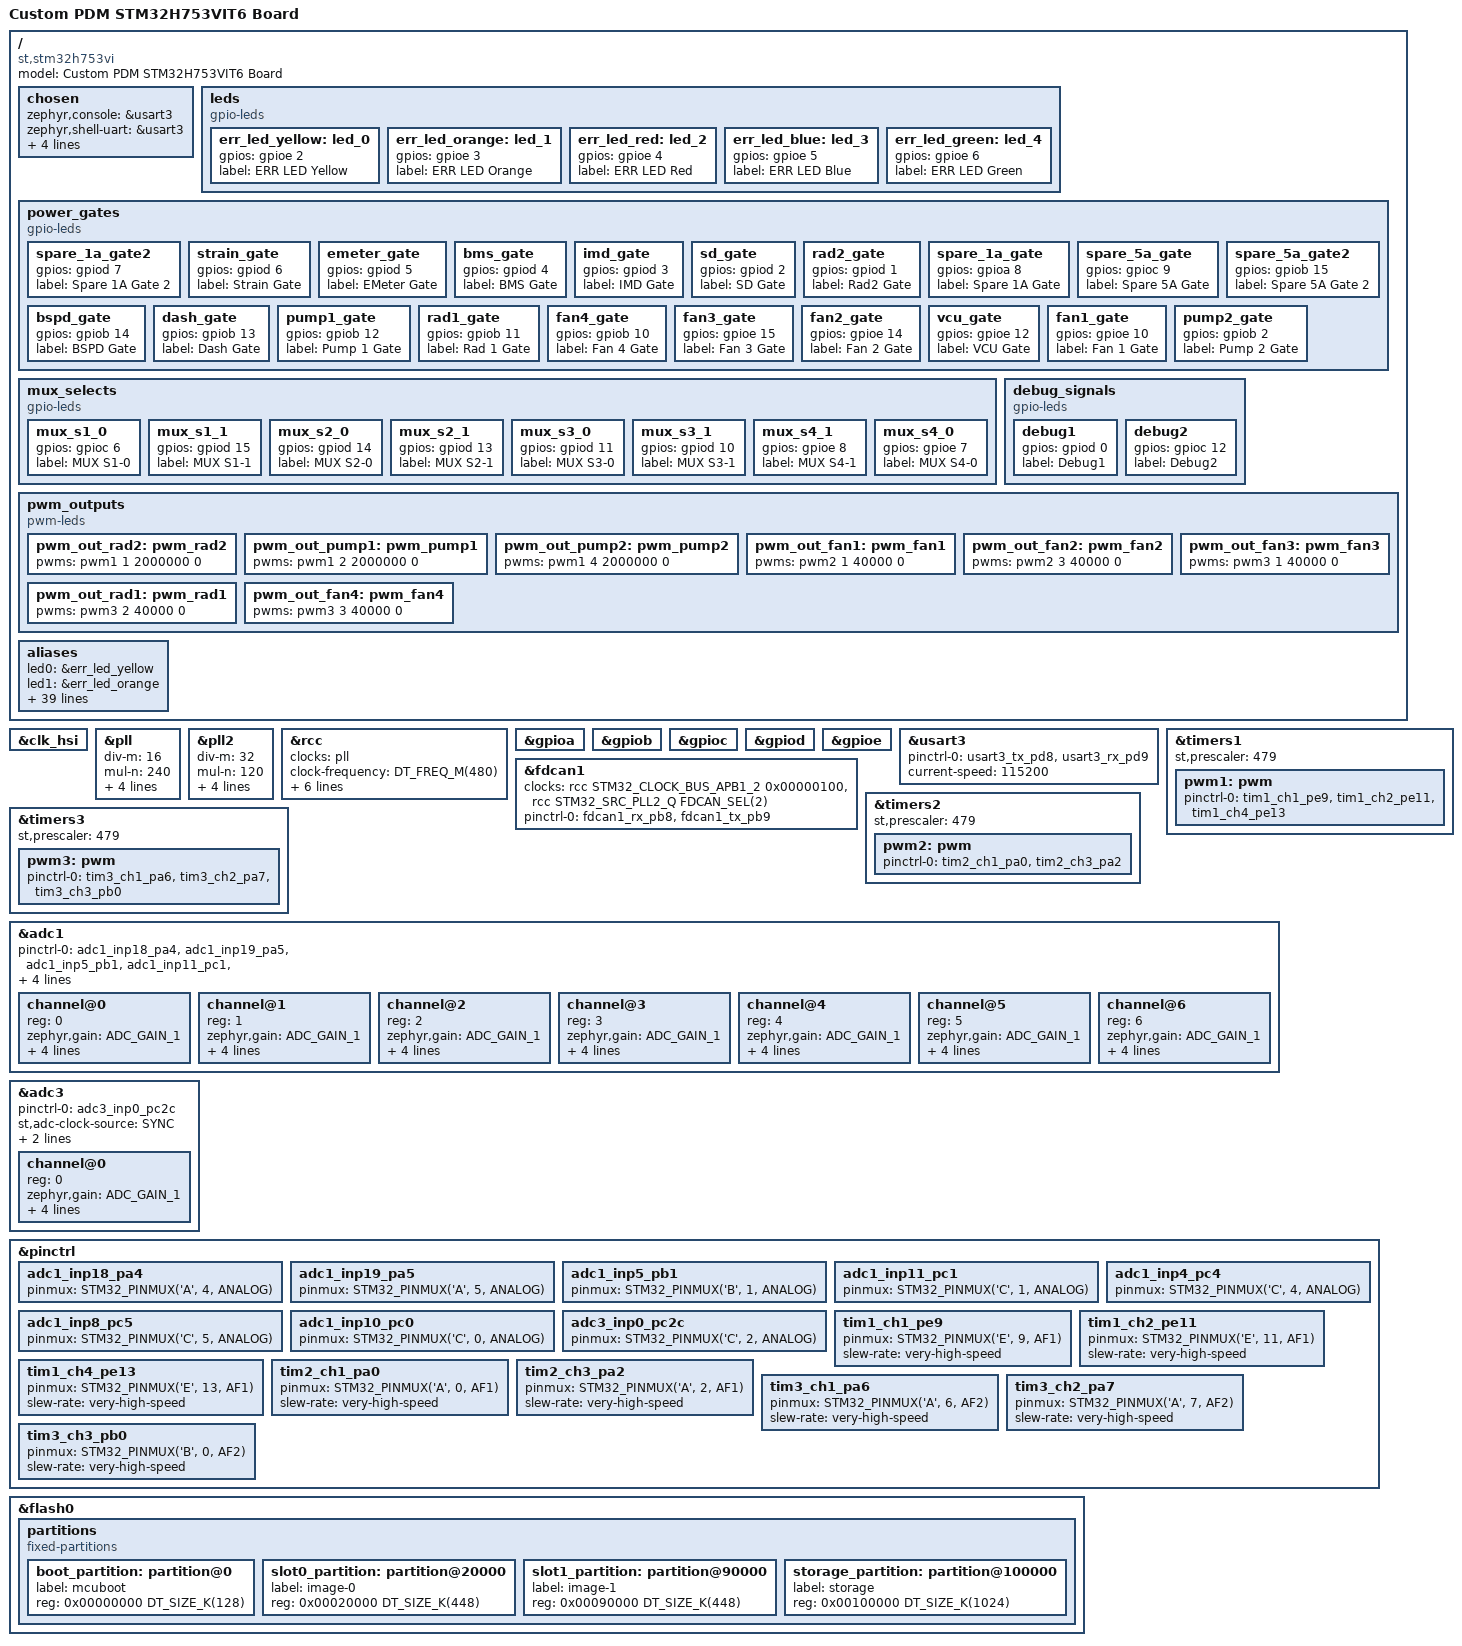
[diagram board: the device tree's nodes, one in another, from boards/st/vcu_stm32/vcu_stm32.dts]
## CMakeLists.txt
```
# SPDX-License-Identifier: Apache-2.0
cmake_minimum_required(VERSION 3.20.0)

#generates compile_commands.json for clangd to LSP correctly. 
set(CMAKE_EXPORT_COMPILE_COMMANDS ON)

set_source_files_properties(src/*.cpp PROPERTIES LANGUAGE CXX)

get_filename_component(_app_root "${CMAKE_CURRENT_SOURCE_DIR}" ABSOLUTE)
set(BOARD_ROOT "${_app_root}")


find_package(Zephyr REQUIRED HINTS $ENV{ZEPHYR_BASE})
project(pdm)

# Add include/ directory to include paths
target_include_directories(app PRIVATE
    ${CMAKE_CURRENT_SOURCE_DIR}/include
)

# Gather all C and C++ source files under src/
file(GLOB_RECURSE APP_SOURCES
    ${CMAKE_CURRENT_SOURCE_DIR}/src/*.c
    ${CMAKE_CURRENT_SOURCE_DIR}/src/*.cpp
)

# Add sources to app target
target_sources(app PRIVATE ${APP_SOURCES})
```

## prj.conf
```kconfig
CONFIG_CAN=y
CONFIG_GPIO=y
CONFIG_ADC=y
CONFIG_LOG=y
CONFIG_PWM=y
CONFIG_LOG_BACKEND_RTT=y
CONFIG_LOG_BACKEND_UART=n
CONFIG_USE_SEGGER_RTT=y
CONFIG_SEGGER_RTT_BUFFER_SIZE_UP=4096
CONFIG_UART_CONSOLE=n
CONFIG_RTT_CONSOLE=y
CONFIG_LOG_MODE_IMMEDIATE=y
CONFIG_LOG_DEFAULT_LEVEL=4
CONFIG_LOG_OVERRIDE_LEVEL=4
CONFIG_TRAP_UNALIGNED_ACCESS=n
CONFIG_LOG_BACKEND_FORMAT_TIMESTAMP=y
CONFIG_LOG_BACKEND_SHOW_COLOR=y
CONFIG_MAIN_STACK_SIZE=8192

CONFIG_FAULT_DUMP=2


CONFIG_CBPRINTF_FP_SUPPORT=y

CONFIG_CPP=y
CONFIG_CPP_EXCEPTIONS=y
CONFIG_GLIBCXX_LIBCPP=y
CONFIG_CAN_STATS=y

# Keep your custom compiler flag:
CONFIG_COMPILER_OPT="-ftrack-macro-expansion=0"
CONFIG_THREAD_MONITOR=y
CONFIG_THREAD_STACK_INFO=y
CONFIG_HEAP_MEM_POOL_SIZE=16384
CONFIG_SYSTEM_WORKQUEUE_STACK_SIZE=2048
CONFIG_SYS_HEAP_RUNTIME_STATS=y
CONFIG_PRINTK=y

CONFIG_ARM_MPU=n

CONFIG_THREAD_RUNTIME_STATS=y
CONFIG_DEBUG_OPTIMIZATIONS=y

CONFIG_SCHED_THREAD_USAGE=y
CONFIG_CPU_LOAD=y
CONFIG_STATS=y
```

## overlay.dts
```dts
    user_button: user_button {
        gpios = <&gpioc 13 GPIO_ACTIVE_LOW>;
        label = "USER_BUTTON";
    };
```

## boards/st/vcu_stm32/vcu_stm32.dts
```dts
/*
 * Copyright (c) 2025 PDM Team
 * SPDX-License-Identifier: Apache-2.0
 */

/dts-v1/;
#include <st/h7/stm32h753Xi.dtsi>
#include <st/h7/stm32h753vitx-pinctrl.dtsi>
#include <zephyr/dt-bindings/input/input-event-codes.h>
#include <zephyr/dt-bindings/gpio/gpio.h>

/ {
	model = "Custom PDM STM32H753VIT6 Board";
	compatible = "st,stm32h753vi";

	chosen {
		zephyr,console    = &usart3;
		zephyr,shell-uart = &usart3;
		zephyr,sram       = &sram0;
		zephyr,flash      = &flash0;
		zephyr,dtcm       = &dtcm;
		zephyr,canbus     = &fdcan1;
	};

	/* ------------------------------------------------------------------ */
	/* Status LEDs                                                          */
	/* ------------------------------------------------------------------ */
	leds {
		compatible = "gpio-leds";
		err_led_yellow: led_0 {
			gpios = <&gpioe 2 GPIO_ACTIVE_HIGH>;
			label = "ERR LED Yellow";
		};
		err_led_orange: led_1 {
			gpios = <&gpioe 3 GPIO_ACTIVE_HIGH>;
			label = "ERR LED Orange";
		};
		err_led_red: led_2 {
			gpios = <&gpioe 4 GPIO_ACTIVE_HIGH>;
			label = "ERR LED Red";
		};
		err_led_blue: led_3 {
			gpios = <&gpioe 5 GPIO_ACTIVE_HIGH>;
			label = "ERR LED Blue";
		};
		err_led_green: led_4 {
			gpios = <&gpioe 6 GPIO_ACTIVE_HIGH>;
			label = "ERR LED Green";
		};
	};

	/* ------------------------------------------------------------------ */
	/* Power Gate Outputs                                                   */
	/* ------------------------------------------------------------------ */
	power_gates {
		compatible = "gpio-leds";

		spare_1a_gate2: spare_1a_gate2 {
			gpios = <&gpiod 7 GPIO_ACTIVE_HIGH>;
			label = "Spare 1A Gate 2";
		};
		strain_gate: strain_gate {
			gpios = <&gpiod 6 GPIO_ACTIVE_HIGH>;
			label = "Strain Gate";
		};
		emeter_gate: emeter_gate {
			gpios = <&gpiod 5 GPIO_ACTIVE_HIGH>;
			label = "EMeter Gate";
		};
		bms_gate: bms_gate {
			gpios = <&gpiod 4 GPIO_ACTIVE_HIGH>;
			label = "BMS Gate";
		};
		imd_gate: imd_gate {
			gpios = <&gpiod 3 GPIO_ACTIVE_HIGH>;
			label = "IMD Gate";
		};
		sd_gate: sd_gate {
			gpios = <&gpiod 2 GPIO_ACTIVE_HIGH>;
			label = "SD Gate";
		};
		rad2_gate: rad2_gate {
			gpios = <&gpiod 1 GPIO_ACTIVE_HIGH>;
			label = "Rad2 Gate";
		};
		spare_1a_gate: spare_1a_gate {
			gpios = <&gpioa 8 GPIO_ACTIVE_HIGH>;
			label = "Spare 1A Gate";
		};
		spare_5a_gate: spare_5a_gate {
			gpios = <&gpioc 9 GPIO_ACTIVE_HIGH>;
			label = "Spare 5A Gate";
		};
		spare_5a_gate2: spare_5a_gate2 {
			gpios = <&gpiob 15 GPIO_ACTIVE_HIGH>;
			label = "Spare 5A Gate 2";
		};
		bspd_gate: bspd_gate {
			gpios = <&gpiob 14 GPIO_ACTIVE_HIGH>;
			label = "BSPD Gate";
		};
		dash_gate: dash_gate {
			gpios = <&gpiob 13 GPIO_ACTIVE_HIGH>;
			label = "Dash Gate";
		};
		pump1_gate: pump1_gate {
			gpios = <&gpiob 12 GPIO_ACTIVE_HIGH>;
			label = "Pump 1 Gate";
		};
		rad1_gate: rad1_gate {
			gpios = <&gpiob 11 GPIO_ACTIVE_HIGH>;
			label = "Rad 1 Gate";
		};
		fan4_gate: fan4_gate {
			gpios = <&gpiob 10 GPIO_ACTIVE_HIGH>;
			label = "Fan 4 Gate";
		};
		fan3_gate: fan3_gate {
			gpios = <&gpioe 15 GPIO_ACTIVE_HIGH>;
			label = "Fan 3 Gate";
		};
		fan2_gate: fan2_gate {
			gpios = <&gpioe 14 GPIO_ACTIVE_HIGH>;
			label = "Fan 2 Gate";
		};
		vcu_gate: vcu_gate {
			gpios = <&gpioe 12 GPIO_ACTIVE_HIGH>;
			label = "VCU Gate";
		};
		fan1_gate: fan1_gate {
			gpios = <&gpioe 10 GPIO_ACTIVE_HIGH>;
			label = "Fan 1 Gate";
		};
		pump2_gate: pump2_gate {
			gpios = <&gpiob 2 GPIO_ACTIVE_HIGH>;
			label = "Pump 2 Gate";
		};
	};

	/* ------------------------------------------------------------------ */
	/* Multiplexer Select Lines                                             */
	/* ------------------------------------------------------------------ */
	mux_selects {
		compatible = "gpio-leds";

		mux_s1_0: mux_s1_0 {
			gpios = <&gpioc 6 GPIO_ACTIVE_HIGH>;
			label = "MUX S1-0";
		};
		mux_s1_1: mux_s1_1 {
			gpios = <&gpiod 15 GPIO_ACTIVE_HIGH>;
			label = "MUX S1-1";
		};
		mux_s2_0: mux_s2_0 {
			gpios = <&gpiod 14 GPIO_ACTIVE_HIGH>;
			label = "MUX S2-0";
		};
		mux_s2_1: mux_s2_1 {
			gpios = <&gpiod 13 GPIO_ACTIVE_HIGH>;
			label = "MUX S2-1";
		};
		mux_s3_0: mux_s3_0 {
			gpios = <&gpiod 11 GPIO_ACTIVE_HIGH>;
			label = "MUX S3-0";
		};
		mux_s3_1: mux_s3_1 {
			gpios = <&gpiod 10 GPIO_ACTIVE_HIGH>;
			label = "MUX S3-1";
		};
		mux_s4_1: mux_s4_1 {
			gpios = <&gpioe 8 GPIO_ACTIVE_HIGH>;
			label = "MUX S4-1";
		};
		mux_s4_0: mux_s4_0 {
			gpios = <&gpioe 7 GPIO_ACTIVE_HIGH>;
			label = "MUX S4-0";
		};
	};

	/* ------------------------------------------------------------------ */
	/* Debug GPIOs                                                          */
	/* ------------------------------------------------------------------ */
	debug_signals {
		compatible = "gpio-leds";

		debug1: debug1 {
			gpios = <&gpiod 0 GPIO_ACTIVE_HIGH>;
			label = "Debug1";
		};
		debug2: debug2 {
			gpios = <&gpioc 12 GPIO_ACTIVE_HIGH>;
			label = "Debug2";
		};
	};

	pwm_outputs {
		compatible = "pwm-leds";

		pwm_out_rad2:  pwm_rad2  { pwms = <&pwm1 1 2000000 0>; };  /* 500Hz  = 2,000,000ns */
		pwm_out_pump1: pwm_pump1 { pwms = <&pwm1 2 2000000 0>; };  /* 500Hz  = 2,000,000ns */
		pwm_out_pump2: pwm_pump2 { pwms = <&pwm1 4 2000000 0>; };  /* 500Hz  = 2,000,000ns */
		pwm_out_fan1:  pwm_fan1  { pwms = <&pwm2 1 40000   0>; };  /* 25kHz  = 40,000ns    */
		pwm_out_fan2:  pwm_fan2  { pwms = <&pwm2 3 40000   0>; };  /* 25kHz  = 40,000ns    */
		pwm_out_fan3:  pwm_fan3  { pwms = <&pwm3 1 40000   0>; };  /* 25kHz  = 40,000ns    */
		pwm_out_rad1:  pwm_rad1  { pwms = <&pwm3 2 40000   0>; };  /* 25kHz  = 40,000ns    */
		pwm_out_fan4:  pwm_fan4  { pwms = <&pwm3 3 40000   0>; };  /* 25kHz  = 40,000ns    */
    	};

	/* ------------------------------------------------------------------ */
	/* Aliases                                                              */
	/* ------------------------------------------------------------------ */
	aliases {
		/* LEDs */
		led0 = &err_led_yellow;
		led1 = &err_led_orange;
		led2 = &err_led_red;
		led3 = &err_led_blue;
		led4 = &err_led_green;

		/* Gates */
		spare-1a-gate2  = &spare_1a_gate2;
		strain-gate     = &strain_gate;
		emeter-gate     = &emeter_gate;
		bms-gate        = &bms_gate;
		imd-gate        = &imd_gate;
		sd-gate         = &sd_gate;
		rad2-gate       = &rad2_gate;
		spare-1a-gate   = &spare_1a_gate;
		spare-5a-gate   = &spare_5a_gate;
		spare-5a-gate2  = &spare_5a_gate2;
		bspd-gate       = &bspd_gate;
		dash-gate       = &dash_gate;
		pump1-gate      = &pump1_gate;
		rad1-gate       = &rad1_gate;
		fan4-gate       = &fan4_gate;
		fan3-gate       = &fan3_gate;
		fan2-gate       = &fan2_gate;
		vcu-gate        = &vcu_gate;
		fan1-gate       = &fan1_gate;
		pump2-gate      = &pump2_gate;

		/* MUX selects */
		mux-s1-0 = &mux_s1_0;
		mux-s1-1 = &mux_s1_1;
		mux-s2-0 = &mux_s2_0;
		mux-s2-1 = &mux_s2_1;
		mux-s3-0 = &mux_s3_0;
		mux-s3-1 = &mux_s3_1;
		mux-s4-1 = &mux_s4_1;
		mux-s4-0 = &mux_s4_0;

		/* PWM */
		pwm-rad2  = &pwm_out_rad2;
		pwm-pump1 = &pwm_out_pump1;
		pwm-pump2 = &pwm_out_pump2;
		pwm-fan1  = &pwm_out_fan1;
		pwm-fan2  = &pwm_out_fan2;
		pwm-fan3  = &pwm_out_fan3;
		pwm-rad1  = &pwm_out_rad1;
		pwm-fan4  = &pwm_out_fan4;

	};
};

/* ====================================================================== */
/* Clocks                                                                  */
/* ====================================================================== */

&clk_hsi {
	status = "okay";
};

&pll {
	div-m = <16>;    /* 64 MHz / 16 =   4 MHz ref             */
	mul-n = <240>;   /*  4 MHz × 240 = 960 MHz VCO            */
	div-p = <2>;     /* 960 / 2 = 480 MHz (SYSCLK)            */
	div-q = <2>;     /* 960 / 2 = 480 MHz                     */
	div-r = <2>;     /* 960 / 2 = 480 MHz                     */
	clocks = <&clk_hsi>;
	status = "okay";
};

&pll2 {
	div-m = <32>;    /* 64 MHz / 32 =   2 MHz ref             */
	mul-n = <120>;   /*  2 MHz × 120 = 240 MHz VCO            */
	div-p = <2>;     /* 240 / 2 = 120 MHz                     */
	div-q = <3>;     /* 240 / 3 =  80 MHz (FDCAN clock)       */
	div-r = <2>;     /* 240 / 2 = 120 MHz                     */
	clocks = <&clk_hsi>;
	status = "okay";
};

&rcc {
	clocks = <&pll>;
	clock-frequency = <DT_FREQ_M(480)>;
	d1cpre  = <1>;
	hpre    = <2>;
	d1ppre  = <2>;
	d2ppre1 = <2>;
	d2ppre2 = <2>;
	d3ppre  = <2>;
};


/* ====================================================================== */
/* GPIO Ports                                                              */
/* ====================================================================== */

&gpioa { status = "okay"; };
&gpiob { status = "okay"; };
&gpioc { status = "okay"; };
&gpiod { status = "okay"; };
&gpioe { status = "okay"; };

/* ====================================================================== */
/* USART3  — PD8 TX / PD9 RX                                              */
/* ====================================================================== */

&usart3 {
	pinctrl-0 = <&usart3_tx_pd8 &usart3_rx_pd9>;
	pinctrl-names = "default";
	current-speed = <115200>;
	status = "okay";
};

/* ====================================================================== */
/* FDCAN1  — PB8 RX / PB9 TX                                              */
/* ====================================================================== */

&fdcan1 {
	clocks = <&rcc STM32_CLOCK_BUS_APB1_2 0x00000100>,
		 <&rcc STM32_SRC_PLL2_Q FDCAN_SEL(2)>;
	pinctrl-0 = <&fdcan1_rx_pb8 &fdcan1_tx_pb9>;
	pinctrl-names = "default";
	status = "okay";
};

/* ====================================================================== */
/* PWM                                                                     */
/* ====================================================================== */

/* TIM1 — Rad2 PWM (PE9/CH1), Pump1 PWM (PE11/CH2), Pump2 PWM (PE13/CH4) */
&timers1 {
	st,prescaler = <479>;  /* 480 MHz / 480 = 1 MHz timer clock */
	status = "okay";

	pwm1: pwm {
		pinctrl-0 = <&tim1_ch1_pe9 &tim1_ch2_pe11 &tim1_ch4_pe13>;
		pinctrl-names = "default";
		status = "okay";
	};
};

/* TIM2 — Fan1 PWM (PA0/CH1), Fan2 PWM (PA2/CH3) */
&timers2 {
	st,prescaler = <479>;
	status = "okay";

	pwm2: pwm {
		pinctrl-0 = <&tim2_ch1_pa0 &tim2_ch3_pa2>;
		pinctrl-names = "default";
		status = "okay";
	};
};

/* TIM3 — Fan3 PWM (PA6/CH1), Rad1 PWM (PA7/CH2), Fan4 PWM (PB0/CH3) */
&timers3 {
	st,prescaler = <479>;
	status = "okay";

	pwm3: pwm {
		pinctrl-0 = <&tim3_ch1_pa6 &tim3_ch2_pa7 &tim3_ch3_pb0>;
		pinctrl-names = "default";
		status = "okay";
	};
};


/* ====================================================================== */
/* ADC1/2 shared channels                                                  */
/*   PA4  — I_10A_Limit  (ADC12_INP18)                                    */
/*   PA5  — I_5A_Limit   (ADC12_INP19)                                    */
/*   PB1  — I_Pump2      (ADC12_INP5)                                     */
/*   PC1  — I_Rad1_Prot  (ADC123_INP11)                                   */
/*   PC4  — I_Pump1      (ADC12_INP4)                                      */
/*   PC5  — I_1a_Limit1  (ADC12_INP8)                                     */
/*   PC0  — I_1a_Limit2  (ADC123_INP10)                                     */
/* ====================================================================== */

&adc1 {
	pinctrl-0 = <&adc1_inp18_pa4
	             &adc1_inp19_pa5
	             &adc1_inp5_pb1
	             &adc1_inp11_pc1
	             &adc1_inp4_pc4
	             &adc1_inp8_pc5
				 &adc1_inp10_pc0>;
	pinctrl-names = "default";
	st,adc-clock-source = "SYNC";
	st,adc-prescaler = <4>;
	vref-mv = <3300>;
	status = "okay";

	#address-cells = <1>;
	#size-cells = <0>;

	channel@0 {
		reg = <0>;
		zephyr,gain             = "ADC_GAIN_1";
		zephyr,reference        = "ADC_REF_VDD_1";
		zephyr,acquisition-time = <ADC_ACQ_TIME_DEFAULT>;
		zephyr,resolution       = <12>;
		zephyr,input-positive   = <18>;  /* PA4 - I_10A_Limit - INP18 */
	};

	channel@1 {
		reg = <1>;
		zephyr,gain             = "ADC_GAIN_1";
		zephyr,reference        = "ADC_REF_VDD_1";
		zephyr,acquisition-time = <ADC_ACQ_TIME_DEFAULT>;
		zephyr,resolution       = <12>;
		zephyr,input-positive   = <19>;  /* PA5 - I_5A_Limit  - INP19 */
	};

	channel@2 {
		reg = <2>;
		zephyr,gain             = "ADC_GAIN_1";
		zephyr,reference        = "ADC_REF_VDD_1";
		zephyr,acquisition-time = <ADC_ACQ_TIME_DEFAULT>;
		zephyr,resolution       = <12>;
		zephyr,input-positive   = <5>;   /* PB1 - I_Pump2     - INP5  */
	};

	channel@3 {
		reg = <3>;
		zephyr,gain             = "ADC_GAIN_1";
		zephyr,reference        = "ADC_REF_VDD_1";
		zephyr,acquisition-time = <ADC_ACQ_TIME_DEFAULT>;
		zephyr,resolution       = <12>;
		zephyr,input-positive   = <11>;  /* PC1 - I_Rad1_Prot - INP11 */
	};

	channel@4 {
		reg = <4>;
		zephyr,gain             = "ADC_GAIN_1";
		zephyr,reference        = "ADC_REF_VDD_1";
		zephyr,acquisition-time = <ADC_ACQ_TIME_DEFAULT>;
		zephyr,resolution       = <12>;
		zephyr,input-positive   = <4>;   /* PC4 - I_Pump1     - INP4  */
	};

	channel@5 {
		reg = <5>;
		zephyr,gain             = "ADC_GAIN_1";
		zephyr,reference        = "ADC_REF_VDD_1";
		zephyr,acquisition-time = <ADC_ACQ_TIME_DEFAULT>;
		zephyr,resolution       = <12>;
		zephyr,input-positive   = <8>;   /* PC5 - I_1a_Limit1 - INP8  */
	};

	channel@6 {
		reg = <6>;
		zephyr,gain             = "ADC_GAIN_1";
		zephyr,reference        = "ADC_REF_VDD_1";
		zephyr,acquisition-time = <ADC_ACQ_TIME_DEFAULT>;
		zephyr,resolution       = <12>;
		zephyr,input-positive   = <8>;   /* PC0 - I_1a_Limit2 - INP10  */
	};
};

/* ====================================================================== */
/* ADC3                                                                    */
/*   PC2_C — I_Rad2_Prot (ADC3_INP0)                                      */
/* ====================================================================== */

&adc3 {
	pinctrl-0 = <&adc3_inp0_pc2c>;
	pinctrl-names = "default";
	st,adc-clock-source = "SYNC";
	st,adc-prescaler = <4>;
	vref-mv = <3300>;
	status = "okay";

	#address-cells = <1>;
	#size-cells = <0>;

	channel@0 {
		reg = <0>;
		zephyr,gain             = "ADC_GAIN_1";
		zephyr,reference        = "ADC_REF_VDD_1";
		zephyr,acquisition-time = <ADC_ACQ_TIME_DEFAULT>;
		zephyr,resolution       = <16>;  /* ADC3 supports 16-bit on H7 */
		zephyr,input-positive   = <0>;   /* PC2_C - I_Rad2_Prot - INP0 */
	};
};

/* ====================================================================== */
/* Custom pinctrl entries                                                  */
/*                                                                         */
/* ADC (ANALOG) and PWM (AF) pins not present in the included pinctrl     */
/* dtsi are defined here.  PWM alternate functions for STM32H753:         */
/*   TIM1 → AF1,  TIM2 → AF1,  TIM3 → AF2                                */
/* ====================================================================== */

&pinctrl {

	/* --- ADC1 --------------------------------------------------------- */
	adc1_inp18_pa4: adc1_inp18_pa4 {
		pinmux = <STM32_PINMUX('A', 4, ANALOG)>;
	};
	adc1_inp19_pa5: adc1_inp19_pa5 {
		pinmux = <STM32_PINMUX('A', 5, ANALOG)>;
	};
	adc1_inp5_pb1: adc1_inp5_pb1 {
		pinmux = <STM32_PINMUX('B', 1, ANALOG)>;
	};
	adc1_inp11_pc1: adc1_inp11_pc1 {
		pinmux = <STM32_PINMUX('C', 1, ANALOG)>;
	};
	adc1_inp4_pc4: adc1_inp4_pc4 {
		pinmux = <STM32_PINMUX('C', 4, ANALOG)>;
	};
	adc1_inp8_pc5: adc1_inp8_pc5 {
		pinmux = <STM32_PINMUX('C', 5, ANALOG)>;
	};
	adc1_inp10_pc0: adc1_inp10_pc0 {
		pinmux = <STM32_PINMUX('C', 0, ANALOG)>;
	};

	/* --- ADC3 --------------------------------------------------------- */
	/* PC2_C is the direct analog pad (no GPIO mux required)              */
	adc3_inp0_pc2c: adc3_inp0_pc2c {
		pinmux = <STM32_PINMUX('C', 2, ANALOG)>;
	};

	/* --- TIM1 (AF1) --------------------------------------------------- */
	tim1_ch1_pe9: tim1_ch1_pe9 {
		pinmux = <STM32_PINMUX('E', 9, AF1)>;
		slew-rate = "very-high-speed";
	};
	tim1_ch2_pe11: tim1_ch2_pe11 {
		pinmux = <STM32_PINMUX('E', 11, AF1)>;
		slew-rate = "very-high-speed";
	};
	tim1_ch4_pe13: tim1_ch4_pe13 {
		pinmux = <STM32_PINMUX('E', 13, AF1)>;
		slew-rate = "very-high-speed";
	};

	/* --- TIM2 (AF1) --------------------------------------------------- */
	tim2_ch1_pa0: tim2_ch1_pa0 {
		pinmux = <STM32_PINMUX('A', 0, AF1)>;
		slew-rate = "very-high-speed";
	};
	tim2_ch3_pa2: tim2_ch3_pa2 {
		pinmux = <STM32_PINMUX('A', 2, AF1)>;
		slew-rate = "very-high-speed";
	};

	/* --- TIM3 (AF2) --------------------------------------------------- */
	tim3_ch1_pa6: tim3_ch1_pa6 {
		pinmux = <STM32_PINMUX('A', 6, AF2)>;
		slew-rate = "very-high-speed";
	};
	tim3_ch2_pa7: tim3_ch2_pa7 {
		pinmux = <STM32_PINMUX('A', 7, AF2)>;
		slew-rate = "very-high-speed";
	};
	tim3_ch3_pb0: tim3_ch3_pb0 {
		pinmux = <STM32_PINMUX('B', 0, AF2)>;
		slew-rate = "very-high-speed";
	};
};

/* ====================================================================== */
/* Flash partitions                                                        */
/* ====================================================================== */

&flash0 {
	partitions {
		compatible = "fixed-partitions";
		#address-cells = <1>;
		#size-cells = <1>;

		boot_partition: partition@0 {
			label = "mcuboot";
			reg = <0x00000000 DT_SIZE_K(128)>;
		};
		slot0_partition: partition@20000 {
			label = "image-0";
			reg = <0x00020000 DT_SIZE_K(448)>;
		};
		slot1_partition: partition@90000 {
			label = "image-1";
			reg = <0x00090000 DT_SIZE_K(448)>;
		};
		storage_partition: partition@100000 {
			label = "storage";
			reg = <0x00100000 DT_SIZE_K(1024)>;
		};
	};
};
```

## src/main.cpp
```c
#include <zephyr/kernel.h>
#include <zephyr/logging/log.h>

#include "hardware.h"
#include "system.h"
#include "vehicle_state.h"
#include "pwm_controller.h"

LOG_MODULE_REGISTER(main);

void send_heartbeat(Hardware &hw)
{
    static uint32_t heartbeat_counter = 0;

    struct can_frame heartbeat_frame = {.id = 0x100, // Heartbeat message ID
                                        .dlc = 8,
                                        .flags = 0,
                                        .data = {(uint8_t)(heartbeat_counter >> 24), (uint8_t)(heartbeat_counter >> 16),
                                                 (uint8_t)(heartbeat_counter >> 8), (uint8_t)(heartbeat_counter), 0xEF,
                                                 0xFF, 0xFF, 0xFF}};

    // int ret = hw.can1.send(&heartbeat_frame, K_NO_WAIT);
    // if (ret == 0)
    // {
    // }
    // else
    // {
    //     LOG_ERR("Heartbeat send failed: %d", ret);
    // }

    heartbeat_counter++;
}

// int main(void)
// {
//     LOG_INF("REACHED MAIN"); /* add this first */
//     k_busy_wait(100000);
//     LOG_INF("AFTER WAIT");
//     LOG_INF("***VCU ENTERED MAIN***\n");

//     static VehicleState vehicle;
//     static Hardware hardware(vehicle);
//     static System system;

//     LOG_INF("=== VCU Starting ===");

//     // Initialize system resources
//     if (system.init() != 0)
//     {
//         LOG_ERR("System init failed!");
//         return -1;
//     }

//     // Initialize hardware
//     if (hardware.init() != 0)
//     {
//         LOG_ERR("Hardware init failed!");
//         return -2;
//     }

//     // Start diagnostics monitoring
//     if (system.start_diagnostics(&hardware) != 0)
//     {
//         LOG_ERR("Failed to start diagnostics!");
//         return -3;
//     }

//     LOG_INF("=== VCU Ready ===");

//     while (1)
//     {
//         hardware.led_green.toggle();
//         send_heartbeat(hardware);
//         LOG_INF("LED BLINKING");

//         k_msleep(500);
//     }
// }
int main(void)
{
    LOG_INF("REACHED MAIN"); /* add this first */
    k_busy_wait(100000);
    LOG_INF("AFTER WAIT");

    LOG_INF("***PDM ENTERED MAIN***");

    static VehicleState vehicle;
    static Hardware hardware(vehicle);
    static System system;
    LOG_INF("=== PDM Starting ===");

    if (system.init() != 0)
    {
        LOG_ERR("System init failed!");
        return -1;
    }

    if (hardware.init() != 0)
    {
        LOG_ERR("Hardware init failed!");
        return -2;
    }

    if (hardware.power_mgr.enable_all() != 0)
    {
        LOG_ERR("Failed to enable all profets");
        return -3;
    };

    // Start diagnostics monitoring
    if (system.start_diagnostics(&hardware) != 0)
    {
        LOG_ERR("Failed to start diagnostics!");
        return -3;
    }

    PwmController *pwm = startPwmController(20);

    LOG_INF("=== PDM Ready, all PROFETs ON ===");

    bool on = true;

    while (1)
    {
        hardware.led_green.toggle();
        send_heartbeat(hardware);
        LOG_INF("LED BLINKING");

        k_msleep(500);
    }
}
```

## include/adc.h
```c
#pragma once
#include "zephyr-common.h"
#include "zephyr/kernel.h"


int init_adc(void);
float get_voltage(void);          // Simple - does ADC read & conversion internally
int16_t get_adc_raw_value(void);  // Get raw value from last read

int16_t get_pedal_current(void); 
```

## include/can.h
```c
#pragma once
#include <zephyr/drivers/can.h>
#include <zephyr/kernel.h>

#include "vehicle_state.h"

using frame_handler_t = void (*)(const struct can_frame *frame, volatile VehicleState *vehicle);

class CanBus
{
  private:
    const struct device *dev_;
    uint32_t bitrate_;
    uint32_t sample_point_;
    bool initialized_;
    bool started_;
    VehicleState *vehicle_;
    uint32_t frames_rec;
    uint32_t frames_sent;

    static void can1_rx_isr(const struct device *dev, struct can_frame *frame, void *self_ptr);
    static void can2_rx_isr(const struct device *dev, struct can_frame *frame, void *self_ptr);
    void dispatch(const struct can_frame *frame);
    int register_handlers();

    frame_handler_t bus_handlers[2048]{nullptr};

  public:
    CanBus();

    int init(const struct device *dev, uint32_t bitrate = 1000000, uint32_t sample_point = 875);
    int start();
    int stop();

    int send(const struct can_frame *frame, k_timeout_t timeout, can_tx_callback_t callback = nullptr,
             void *user_data = nullptr);

    int add_rx_filter_msgq(struct k_msgq *msgq, const struct can_filter *filter);
    void remove_rx_filter(int filter_id);

    int get_state(enum can_state *state) const;
    int set_mode(can_mode_t mode);
    can_mode_t get_mode() const;

    bool is_initialized() const
    {
        return initialized_;
    }
    bool is_started() const
    {
        return started_;
    }

    const struct device *get_device() const
    {
        return dev_;
    }
};
```

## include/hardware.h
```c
#pragma once

// hardware.h
#include "adc.h"
#include "can.h"
#include "gpio.h" // assumed wrapper matching the .init(port, pin, flags) API
#include "power_manager.h"
#include "vehicle_state.h"
#include <zephyr/device.h>

class Hardware
{
  public:
    Hardware(VehicleState &state);
    int init();

    /* ------------------------------------------------------------------ */
    /* ADC channels                                                        */
    /* ------------------------------------------------------------------ */
    AdcChannel i_10a_limit; /* PA4  - ADC1_INP18 */
    AdcChannel i_5a_limit;  /* PA5  - ADC1_INP19 */
    AdcChannel i_pump2;     /* PB1  - ADC1_INP5  */
    AdcChannel i_rad1_prot; /* PC1  - ADC1_INP11 */
    AdcChannel i_pump1;     /* PC4  - ADC1_INP4  */
    AdcChannel i_1a_limit1; /* PC5  - ADC1_INP8  */
    AdcChannel i_1a_limit2; /* PC0  - ADC123_INP10  */
    AdcChannel i_rad2_prot; /* PC2_C- ADC3_INP0  */

    /* ------------------------------------------------------------------ */
    /* Status LEDs                                                         */
    /* ------------------------------------------------------------------ */
    GpioPin led_yellow; /* PE2 */
    GpioPin led_orange; /* PE3 */
    GpioPin led_red;    /* PE4 */
    GpioPin led_blue;   /* PE5 */
    GpioPin led_green;  /* PE6 */

    /* ------------------------------------------------------------------ */
    /* Power gate outputs                                                  */
    /* ------------------------------------------------------------------ */
    GpioPin spare_1a_gate;  /* PA8  */
    GpioPin spare_5a_gate2; /* PB15 */
    GpioPin bspd_gate;      /* PB14 */
    GpioPin dash_gate;      /* PB13 */
    GpioPin pump1_gate;     /* PB12 */
    GpioPin rad1_gate;      /* PB11 */
    GpioPin fan4_gate;      /* PB10 */
    GpioPin pump2_gate;     /* PB2  */
    GpioPin spare_5a_gate;  /* PC9  */
    GpioPin spare_1a_gate2; /* PD7  */
    GpioPin strain_gate;    /* PD6  */
    GpioPin emeter_gate;    /* PD5  */
    GpioPin bms_gate;       /* PD4  */
    GpioPin imd_gate;       /* PD3  */
    GpioPin sd_gate;        /* PD2  */
    GpioPin rad2_gate;      /* PD1  */
    GpioPin fan3_gate;      /* PE15 */
    GpioPin fan2_gate;      /* PE14 */
    GpioPin vcu_gate;       /* PE12 */
    GpioPin fan1_gate;      /* PE10 */

    /* ------------------------------------------------------------------ */
    /* Multiplexer select lines                                            */
    /* ------------------------------------------------------------------ */
    GpioPin mux_s1_0; /* PC6  */
    GpioPin mux_s1_1; /* PD15 */
    GpioPin mux_s2_0; /* PD14 */
    GpioPin mux_s2_1; /* PD13 */
    GpioPin mux_s3_0; /* PD11 */
    GpioPin mux_s3_1; /* PD10 */
    GpioPin mux_s4_1; /* PE8  */
    GpioPin mux_s4_0; /* PE7  */

    /* ------------------------------------------------------------------ */
    /* Debug GPIOs                                                         */
    /* ------------------------------------------------------------------ */
    GpioPin debug1; /* PD0  */
    GpioPin debug2; /* PC12 */

    /* ------------------------------------------------------------------ */
    /* CAN                                                                 */
    /* ------------------------------------------------------------------ */
    CanBus can1;

    /* ------------------------------------------------------------------ */
    /* Power management                                                    */
    /* ------------------------------------------------------------------ */
    PowerManager power_mgr;

  private:
    int initializeADCs();
    int initializeGPIOs();
    int initializeCANs();
    int initializePowerManager();

    /* GPIO port handles */
    const device *gpioa_{nullptr};
    const device *gpiob_{nullptr};
    const device *gpioc_{nullptr};
    const device *gpiod_{nullptr};
    const device *gpioe_{nullptr};

    /* ADC device handles */
    const device *adc1_dev_{nullptr};
    const device *adc3_dev_{nullptr};

    /* CAN device handle */
    const device *can1_dev_{nullptr};

    VehicleState vehicle;
};
```

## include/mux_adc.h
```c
#pragma once

// mux_adc.h
//
// Models a 2-bit analog multiplexer feeding a single ADC input.
//
// Select line truth table (S1 = MSB, S0 = LSB):
//   S1=0, S0=0  →  channel 0  (binary 00)
//   S1=0, S0=1  →  channel 1  (binary 01)
//   S1=1, S0=0  →  channel 2  (binary 10)
//   S1=1, S0=1  →  channel 3  (binary 11)
//
// A brief settling delay is inserted after the select lines change before
// the ADC is sampled.  Tune SETTLE_US for your mux + RC filter combination.

#include "adc.h"
#include "gpio.h"
#include <cstdint>

class MuxAdcChannel
{
  public:
    /// Settling time in microseconds after changing select lines.
    static constexpr uint32_t SETTLE_US = 10U;

    MuxAdcChannel() = default;

    /// @param s0     Select bit-0 (LSB) GPIO pin
    /// @param s1     Select bit-1 (MSB) GPIO pin
    /// @param adc    ADC channel connected to the mux output
    /// @param name   Label used in log messages
    int init(GpioPin *s0, GpioPin *s1, AdcChannel *adc, const char *name);

    /// Select mux input [0..3], wait for settling, then return raw ADC count.
    int16_t read_raw(uint8_t channel);

    /// Select mux input [0..3], wait for settling, then return voltage in V.
    float read_voltage(uint8_t channel);

    const char *name() const
    {
        return name_;
    }
    bool is_ready() const
    {
        return initialized_;
    }

  private:
    GpioPin *s0_{nullptr};
    GpioPin *s1_{nullptr};
    AdcChannel *adc_{nullptr};
    const char *name_{"?"};
    bool initialized_{false};

    /// Drive select lines to address [0..3].
    void select(uint8_t channel);
};
```

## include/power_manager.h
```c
#pragma once

// power_manager.h
//
// Owns every PROFET channel and the four analog multiplexers on the PDM.
//
// Mux routing
// ───────────
//  MUX S1  select: PC6(S0) / PD15(S1)   ADC output: PC5  / I_1a_Limit1 (INP8)
//    ch 0 (00) → IMD current
//    ch 1 (01) → BSPD current
//    ch 2 (10) → BMS current
//    ch 3 (11) → Spare 1A current
//
//  MUX S2  select: PD14(S0) / PD13(S1)  ADC output: PC0 / I_1A_Limit_2  (INP10)
//    ch 0 (00) → VCU current
//    ch 1 (01) → EMeter current
//    ch 2 (10) → Spare 1A 2 current
//    ch 3 (11) → Strain current
//
//  MUX S3  select: PD11(S0) / PD10(S1)  ADC output: PA5  / I_5A_Limit  (INP19)
//    ch 0 (00) → Dash current
//    ch 1 (01) → Spare 5A current
//    ch 2 (10) → Spare 5A 2 current
//    ch 3 (11) → SD current
//
//  MUX S4  select: PE7(S0)  / PE8(S1)   ADC output: PA4  / I_10A_Limit (INP18)
//    ch 0 (00) → Fan 1 current
//    ch 1 (01) → Fan 2 current
//    ch 2 (10) → Fan 3 current
//    ch 3 (11) → Fan 4 current
//
// Direct ADC (no mux):
//   pump1  → PC4 / I_Pump1  (ADC1_INP4)
//   pump2  → PB1 / I_Pump2  (ADC1_INP5)
//   rad1   → PC1 / I_Rad1_Prot (ADC1_INP11)
//   rad2   → PC2_C / I_Rad2_Prot (ADC3_INP0)
//

#include "adc.h"
#include "gpio.h"
#include "mux_adc.h"
#include "profet.h"
#include <cstdint>

/* -------------------------------------------------------------------------- */
/* CAN-driven enable flags (3 bytes, 1 bit per channel)                       */
/* -------------------------------------------------------------------------- */
struct PdmFlags
{
    /* Pumps & radiators */
    uint8_t pump1 : 1;
    uint8_t pump2 : 1;
    uint8_t rad1 : 1;
    uint8_t rad2 : 1;

    /* Fan gates (PWM duty is controlled separately via TIM) */
    uint8_t fan1 : 1;
    uint8_t fan2 : 1;
    uint8_t fan3 : 1;
    uint8_t fan4 : 1;

    /* Safety / control */
    uint8_t bspd : 1;
    uint8_t dash : 1;
    uint8_t vcu : 1;
    uint8_t bms : 1;
    uint8_t imd : 1;
    uint8_t sd : 1;

    /* Sensing / ancillary */
    uint8_t emeter : 1;
    uint8_t strain : 1;

    /* Spare outputs */
    uint8_t spare_1a : 1;
    uint8_t spare_1a_2 : 1;
    uint8_t spare_5a : 1;
    uint8_t spare_5a_2 : 1;

    uint8_t _reserved : 4;
};
static_assert(sizeof(PdmFlags) == 3, "PdmFlags must be 3 bytes");

/* -------------------------------------------------------------------------- */
/* PowerManager                                                                */
/* -------------------------------------------------------------------------- */
class PowerManager
{
  public:
    PowerManager() = default;

    /* --------------------------------------------------------------------- */
    /* Optional kILIS overrides — call before init()                         */
    /* --------------------------------------------------------------------- */
    void set_k_ilis_pump1(float k)
    {
        k_pump1_ = k;
    }
    void set_k_ilis_pump2(float k)
    {
        k_pump2_ = k;
    }
    void set_k_ilis_rad1(float k)
    {
        k_rad1_ = k;
    }
    void set_k_ilis_rad2(float k)
    {
        k_rad2_ = k;
    }
    void set_k_ilis_fans(float k)
    {
        k_fans_ = k;
    }
    void set_k_ilis_5a(float k)
    {
        k_5a_ = k;
    }
    void set_k_ilis_1a(float k)
    {
        k_1a_ = k;
    }

    /* --------------------------------------------------------------------- */
    /* Initialisation                                                         */
    /*                                                                        */
    /* All GpioPin and AdcChannel objects must already be init()'d before    */
    /* calling this.  Pass the mux select pins and ADC outputs; PowerManager */
    /* builds the MuxAdcChannel objects internally.                          */
    /* --------------------------------------------------------------------- */
    int init(
        /* --- Gate pins ---------------------------------------------------- */
        GpioPin *gate_pump1, GpioPin *gate_pump2, GpioPin *gate_rad1, GpioPin *gate_rad2, GpioPin *gate_fan1,
        GpioPin *gate_fan2, GpioPin *gate_fan3, GpioPin *gate_fan4, GpioPin *gate_bspd, GpioPin *gate_dash,
        GpioPin *gate_vcu, GpioPin *gate_bms, GpioPin *gate_imd, GpioPin *gate_sd, GpioPin *gate_emeter,
        GpioPin *gate_strain, GpioPin *gate_spare_1a, GpioPin *gate_spare_1a_2, GpioPin *gate_spare_5a,
        GpioPin *gate_spare_5a_2,

        /* --- Direct ADC (no mux) ------------------------------------------ */
        AdcChannel *adc_pump1, /* PC4  / INP4  */
        AdcChannel *adc_pump2, /* PB1  / INP5  */
        AdcChannel *adc_rad1,  /* PC1  / INP11 */
        AdcChannel *adc_rad2,  /* PC2_C/ INP0  */

        /* --- Mux select GPIO pairs ---------------------------------------- */
        /* S1 */ GpioPin *s1_s0, GpioPin *s1_s1, AdcChannel *adc_s1_out,
        /* S2 */ GpioPin *s2_s0, GpioPin *s2_s1, AdcChannel *adc_s2_out,
        /* S3 */ GpioPin *s3_s0, GpioPin *s3_s1, AdcChannel *adc_s3_out,
        /* S4 */ GpioPin *s4_s0, GpioPin *s4_s1, AdcChannel *adc_s4_out);

    /* --------------------------------------------------------------------- */
    /* Flag-driven control — call from CAN receive handler                   */
    /* --------------------------------------------------------------------- */
    int apply_flags(const PdmFlags &flags);

    /* --------------------------------------------------------------------- */
    /* Bulk helpers                                                           */
    /* --------------------------------------------------------------------- */
    int enable_all();
    int disable_all();
    void log_currents();

    /* --------------------------------------------------------------------- */
    /* Per-channel accessors                                                  */
    /* --------------------------------------------------------------------- */
    Profet &pump1()
    {
        return pump1_;
    }
    Profet &pump2()
    {
        return pump2_;
    }
    Profet &rad1()
    {
        return rad1_;
    }
    Profet &rad2()
    {
        return rad2_;
    }
    Profet &fan1()
    {
        return fan1_;
    }
    Profet &fan2()
    {
        return fan2_;
    }
    Profet &fan3()
    {
        return fan3_;
    }
    Profet &fan4()
    {
        return fan4_;
    }
    Profet &bspd()
    {
        return bspd_;
    }
    Profet &dash()
    {
        return dash_;
    }
    Profet &vcu()
    {
        return vcu_;
    }
    Profet &bms()
    {
        return bms_;
    }
    Profet &imd()
    {
        return imd_;
    }
    Profet &sd()
    {
        return sd_;
    }
    Profet &emeter()
    {
        return emeter_;
    }
    Profet &strain()
    {
        return strain_;
    }
    Profet &spare_1a()
    {
        return spare_1a_;
    }
    Profet &spare_1a_2()
    {
        return spare_1a_2_;
    }
    Profet &spare_5a()
    {
        return spare_5a_;
    }
    Profet &spare_5a_2()
    {
        return spare_5a_2_;
    }

    /* Mux accessors (for diagnostics / manual reads) */
    MuxAdcChannel &mux_s1()
    {
        return mux_s1_;
    }
    MuxAdcChannel &mux_s2()
    {
        return mux_s2_;
    }
    MuxAdcChannel &mux_s3()
    {
        return mux_s3_;
    }
    MuxAdcChannel &mux_s4()
    {
        return mux_s4_;
    }

  private:
    /* kILIS values — defaults applied in init() if not overridden */
    float k_pump1_ = 0.0f;
    float k_pump2_ = 0.0f;
    float k_rad1_ = 0.0f;
    float k_rad2_ = 0.0f;
    float k_fans_ = 0.0f; /* applied to fan1-4   */
    float k_5a_ = 0.0f;   /* applied to dash, spare5a*, sd */
    float k_1a_ = 0.0f;   /* applied to imd, bspd, bms, spare1a*, vcu, emeter, strain */

    /* Multiplexers */
    MuxAdcChannel mux_s1_;
    MuxAdcChannel mux_s2_;
    MuxAdcChannel mux_s3_;
    MuxAdcChannel mux_s4_;

    /* PROFET channels */
    /* Direct sense */
    Profet pump1_{"pump1"};
    Profet pump2_{"pump2"};
    Profet rad1_{"rad1"};
    Profet rad2_{"rad2"};
    /* MUX S1 */
    Profet imd_{"imd"};
    Profet bspd_{"bspd"};
    Profet bms_{"bms"};
    Profet spare_1a_{"spare_1a"};
    /* MUX S2 */
    Profet vcu_{"vcu"};
    Profet emeter_{"emeter"};
    Profet spare_1a_2_{"spare_1a_2"};
    Profet strain_{"strain"};
    /* MUX S3 */
    Profet dash_{"dash"};
    Profet spare_5a_{"spare_5a"};
    Profet spare_5a_2_{"spare_5a_2"};
    Profet sd_{"sd"};
    /* MUX S4 */
    Profet fan1_{"fan1"};
    Profet fan2_{"fan2"};
    Profet fan3_{"fan3"};
    Profet fan4_{"fan4"};

    bool initialized_{false};

    static int apply_one(Profet &ch, bool enable);
};
```

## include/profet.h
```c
#pragma once

// profet.h
//
// Models a single Infineon PROFET high-side switch channel.
//
// Each PROFET has:
//   - An IN pin  (GpioPin)  : drives the gate HIGH to turn the load on
//   - A sense input, one of:
//       a) Direct AdcChannel   — wired straight to the IS pin
//       b) MuxAdcChannel       — IS pin feeds one of 4 mux inputs;
//                                mux_channel selects which input to read
//
// Current measurement
// -------------------
//   V_IS    = I_IS * R_SENSE
//   I_IS    = I_LOAD / kILIS
//   ∴ I_LOAD = (V_IS / R_SENSE) * kILIS
//
// kILIS is device-specific (check "Sense Current Ratio" in the datasheet).

#include "adc.h"
#include "gpio.h"
#include "mux_adc.h"
#include <cstdint>

class Profet
{
  public:
    /* --------------------------------------------------------------------- */
    /* Construction                                                           */
    /* --------------------------------------------------------------------- */
    Profet() : name_("?"), k_ilis_(0.0f), r_sense_(1200.0f)
    {
    }
    Profet(const char *name, float k_ilis = 0.0f, float r_sense = 1200.0f);

    /* --------------------------------------------------------------------- */
    /* Initialisation — pick ONE of the three overloads                      */
    /* --------------------------------------------------------------------- */

    /// Gate only — no current sensing.
    int init(GpioPin *gate);

    /// Gate + direct AdcChannel wired to the IS/sense output.
    int init(GpioPin *gate, AdcChannel *adc);

    /// Gate + muxed ADC: IS pin feeds mux input [mux_channel] (0-3).
    int init(GpioPin *gate, MuxAdcChannel *mux, uint8_t mux_channel);

    /* --------------------------------------------------------------------- */
    /* Control                                                                */
    /* --------------------------------------------------------------------- */
    int enable();
    int disable();
    int toggle();
    bool is_enabled() const
    {
        return enabled_;
    }

    /* --------------------------------------------------------------------- */
    /* Current sensing                                                        */
    /* --------------------------------------------------------------------- */

    /// Load current in amps, or -1.0f if sensing is not configured.
    float read_current_amps();

    /// Raw ADC count from the IS path, or -1 if unavailable.
    int16_t read_current_raw();

    bool has_current_sense() const
    {
        return sense_mode_ != SenseMode::NONE;
    }

    /* --------------------------------------------------------------------- */
    /* Misc                                                                   */
    /* --------------------------------------------------------------------- */
    const char *name() const
    {
        return name_;
    }

  private:
    enum class SenseMode : uint8_t
    {
        NONE,
        DIRECT,
        MUXED
    };

    const char *name_;
    GpioPin *gate_{nullptr};

    SenseMode sense_mode_{SenseMode::NONE};
    AdcChannel *direct_adc_{nullptr}; /* used when DIRECT */
    MuxAdcChannel *mux_{nullptr};     /* used when MUXED  */
    uint8_t mux_channel_{0};          /* used when MUXED  */

    float k_ilis_;
    float r_sense_;
    bool enabled_{false};
    bool initialized_{false};
};
```

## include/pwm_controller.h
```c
// pwm_controller.hpp
#pragma once

#include <zephyr/kernel.h>
#include <zephyr/drivers/pwm.h>
#include <zephyr/logging/log.h>

#define PWM_PERIOD_TIM1_NS 2000000U // 500Hz  - rad2, pump1, pump2
#define PWM_PERIOD_TIM2_NS 40000U   // 25kHz  - fan1, fan2
#define PWM_PERIOD_TIM3_NS 40000U   // 25kHz  - fan3, rad1, fan4

struct PwmOutput
{
    const struct pwm_dt_spec spec;
    const char *name;
    uint32_t period_ns;
    uint32_t duty_ns;
};

class PwmController
{
  public:
    PwmController();

    // Set all PWM outputs to the same duty cycle (0-100)
    int setAll(uint8_t duty_percent);

    // Set individual PWM outputs (0-100)
    int setRad1(uint8_t duty_percent);
    int setRad2(uint8_t duty_percent);
    int setPump1(uint8_t duty_percent);
    int setPump2(uint8_t duty_percent);
    int setFan1(uint8_t duty_percent);
    int setFan2(uint8_t duty_percent);
    int setFan3(uint8_t duty_percent);
    int setFan4(uint8_t duty_percent);

    // Thread entry
    void run();

    static void threadEntry(void *p1, void *p2, void *p3)
    {
        static_cast<PwmController *>(p1)->run();
    }

  private:
    int applyDuty(PwmOutput &output, uint8_t duty_percent);
    int setChannel(size_t index, uint8_t duty_percent);

    // PWM outputs indexed for easy iteration
    enum Channel
    {
        RAD2 = 0,
        PUMP1,
        PUMP2,
        FAN1,
        FAN2,
        FAN3,
        RAD1,
        FAN4,
        CHANNEL_COUNT
    };

    PwmOutput outputs[CHANNEL_COUNT];
    uint8_t global_duty;
};

PwmController *startPwmController(uint8_t initial_duty);
```

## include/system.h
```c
#pragma once
#include <zephyr/kernel.h>
#include <zephyr/sys/sys_heap.h>
#include <zephyr/sys/mem_stats.h>
#include <zephyr/debug/cpu_load.h>
#include "hardware.h"

class System
{
  private:
    static constexpr size_t HEAP_SIZE = 2048;
    static constexpr int DIAG_THREAD_STACK_SIZE = 1024;
    static constexpr int DIAG_THREAD_PRIORITY = 5;
    static constexpr int DIAG_PERIOD_MS = 1000;

    struct k_heap heap_;
    struct k_thread diag_thread_;
    k_thread_stack_t *diag_stack_;

    Hardware *hardware_;
    bool initialized_;
    bool diagnostics_running_;

    static void diagnostics_thread_entry(void *p1, void *p2, void *p3);
    void diagnostics_loop();

  public:
    System();

    int init();
    int start_diagnostics(Hardware *hw);
    void stop_diagnostics();

    void *heap_alloc(size_t size, k_timeout_t timeout);
    void heap_free(void *ptr);
    int get_heap_stats(struct sys_memory_stats *stats);

    uint64_t get_uptime_ms() const;
    uint8_t get_cpu_load() const;

    bool is_initialized() const
    {
        return initialized_;
    }
};
```

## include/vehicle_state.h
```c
// vehicle_state.h
#pragma once
#include <zephyr/kernel.h>
#include <zephyr/drivers/can.h>

enum Corner : uint8_t
{
    FRONT_LEFT = 0,
    FRONT_RIGHT = 1,
    REAR_LEFT = 2,
    REAR_RIGHT = 3,
    NUM_CORNERS = 4
};

struct DTI_Inverter
{
    uint8_t node_id;

    // Packet 0x1F: General Data 6
    uint8_t control_mode;    // 1=Speed,2=Current,3=CurrBrake,4=Pos,7=None
    int16_t target_iq;       // [A_pk * 10]
    uint16_t motor_position; // [deg * 10]
    uint8_t is_motor_still;  // 1=still, 0=rotating

    // Packet 0x20: General Data 1
    int32_t erpm;          // [ERPM]
    int16_t duty_cycle;    // [% * 10]
    int16_t input_voltage; // [V]

    // Packet 0x21: General Data 2
    int16_t ac_current; // [A_pk * 10]
    int16_t dc_current; // [A_dc * 10]

    // Packet 0x22: General Data 3
    int16_t controller_temp; // [°C * 10]
    int16_t motor_temp;      // [°C * 10]
    uint8_t fault_code;      // 0x00=None ... 0x0A=AnalogErr

    // Packet 0x23: General Data 4
    int32_t id; // [A_pk * 100]
    int32_t iq; // [A_pk * 100]

    // Packet 0x24: General Data 5
    int8_t throttle_signal; // [%]
    int8_t brake_signal;    // [%]

    bool digital_in1;
    bool digital_in2;
    bool digital_in3;
    bool digital_in4;
    bool digital_out1;
    bool digital_out2;
    bool digital_out3;
    bool digital_out4;

    bool drive_enable;

    bool limit_cap_temp;
    bool limit_dc_current;
    bool limit_drive_enable;
    bool limit_igbt_accel_temp;
    bool limit_igbt_temp;
    bool limit_input_voltage;
    bool limit_motor_accel_temp;
    bool limit_motor_temp;
    bool limit_rpm_min;
    bool limit_rpm_max;
    bool limit_power;

    uint8_t can_map_version;

    // Packet 0x25: Configured and Available AC Currents
    int16_t max_ac_current;       // [A_pk * 10]
    int16_t avail_max_ac_current; // [A_pk * 10]
    int16_t min_ac_current;       // [A_pk * 10]
    int16_t avail_min_ac_current; // [A_pk * 10]

    // Packet 0x26: Configured and Available DC Currents
    int16_t max_dc_current;       // [A_dc * 10]
    int16_t avail_max_dc_current; // [A_dc * 10]
    int16_t min_dc_current;       // [A_dc * 10]
    int16_t avail_min_dc_current; // [A_dc * 10]

    uint64_t last_rx_time_ms;
};

struct Analog
{
    uint16_t channels[8];
};

enum APPS_ERRORS
{
    PEDAL_AGREEMENT = 0,
    SHORT_CIRCUIT_P1 = 1,
    SHORT_CIRCUIT_P2 = 2,
    OPEN_CIRCUIT_P1 = 3,
    OPEN_CIRCUIT_P2 = 4,
    BRAKE_OVERLAP = 5,
    NUM_ERRORS = 8,
};

enum PEDAL_SLOPE_DIRECTION
{
    POSITIVE,
    NEGATIVE
};

namespace APPS_CONSTEXPRS
{
static constexpr uint16_t calculateRange(uint16_t highThreshold, uint16_t lowThreshold)
{
    return (highThreshold > lowThreshold) ? (highThreshold - lowThreshold) : (lowThreshold - highThreshold);
}

static constexpr PEDAL_SLOPE_DIRECTION PEDAL_SLOPE_DIRECTION(uint16_t highThreshold, uint16_t lowThreshold)
{
    return (highThreshold > lowThreshold) ? POSITIVE : NEGATIVE;
}

} // namespace APPS_CONSTEXPRS

struct APPS_data
{
    bool errors[APPS_ERRORS::NUM_ERRORS];

    // calibration values, constexpr set at compile time
    static constexpr int pedal1_adc_channel_num = 0;
    static constexpr int pedal2_adc_channel_num = 1;
    static constexpr uint16_t pedal1_low_threshold = 10000;
    static constexpr uint16_t pedal2_low_threshold = 10000;
    static constexpr uint16_t pedal1_high_threshold = 20000;
    static constexpr uint16_t pedal2_high_threshold = 20000;

    static constexpr int brake_main_adc_channel_num = 0;

    // other calibration values
    static constexpr float agreement_threshold = 0.10f; // 10% disagreement
    static constexpr int agreement_timeout_ms = 100;
    static constexpr float brake_on_threshold = 0.25f;  // throttle % to latch brake fault
    static constexpr float brake_off_threshold = 0.05f; // throttle % to clear brake fault

    // constexpr values that are calculated at compiletime
    static constexpr uint16_t pedal1_range_width =
        APPS_CONSTEXPRS::calculateRange(pedal1_high_threshold, pedal1_low_threshold);
    static constexpr uint16_t pedal2_range_width =
        APPS_CONSTEXPRS::calculateRange(pedal2_high_threshold, pedal2_low_threshold);
    static constexpr PEDAL_SLOPE_DIRECTION pedal1_slope_direction =
        APPS_CONSTEXPRS::PEDAL_SLOPE_DIRECTION(pedal1_high_threshold, pedal1_low_threshold);
    static constexpr PEDAL_SLOPE_DIRECTION pedal2_slope_direction =
        APPS_CONSTEXPRS::PEDAL_SLOPE_DIRECTION(pedal2_high_threshold, pedal2_low_threshold);

    // IN PERCENTAGE, translation of input voltages to output command AFTER APPS processing
    float commandedTorquePercentage;
    float pedal1_percent;
    float pedal2_percent;
};

// struct that provides access to sub  Interface structs that house publicly accessible data to whole program.
// classes that interact with vehicle state should refer to this struct as source of truth
class VehicleState
{
  public:
    DTI_Inverter INVERTERS[Corner::NUM_CORNERS];
    Analog analogIf;
    APPS_data APPSIf;
};
```
